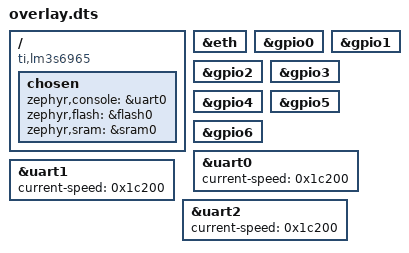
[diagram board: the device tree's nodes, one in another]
/ {
	compatible = "ti,lm3s6965", "ti,lm3s6965evb-qemu";
	chosen {
		zephyr,console = &uart0;
		zephyr,flash = &flash0;
		zephyr,sram = &sram0;
	};
};
&eth{
	status = "okay";
};
&gpio0{
	status = "okay";
};
&gpio1{
	status = "okay";
};
&gpio2{
	status = "okay";
};
&gpio3{
	status = "okay";
};
&gpio4{
	status = "okay";
};
&gpio5{
	status = "okay";
};
&gpio6{
	status = "okay";
};
&uart0{
	status = "okay";
	current-speed = < 0x1c200 >;
};
&uart1{
	status = "okay";
	current-speed = < 0x1c200 >;
};
&uart2{
	status = "okay";
	current-speed = < 0x1c200 >;
};
